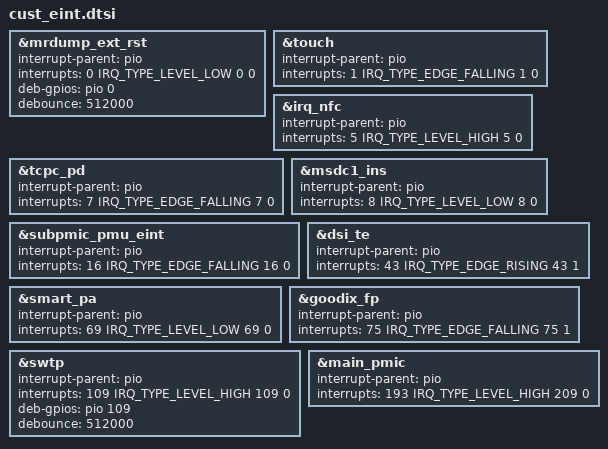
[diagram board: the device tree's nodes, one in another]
/*
 * Generated by MTK SP DrvGen Version: 3.5.160809 for MT6785.
 * 2024-09-29 07:04:17
 * Do Not Modify The File.
 * Copyright Mediatek Inc. (c) 2016.
*/

/*************************
 * EINT DTSI File
*************************/

#include <dt-bindings/interrupt-controller/irq.h>
#include <dt-bindings/interrupt-controller/arm-gic.h>

&mrdump_ext_rst {
	interrupt-parent = <&pio>;
	interrupts = <0 IRQ_TYPE_LEVEL_LOW 0 0>;
	deb-gpios = <&pio 0 0>;
	debounce = <512000>;
	status = "okay";
};

&touch {
	interrupt-parent = <&pio>;
	interrupts = <1 IRQ_TYPE_EDGE_FALLING 1 0>;
	status = "okay";
};

&irq_nfc {
	interrupt-parent = <&pio>;
	interrupts = <5 IRQ_TYPE_LEVEL_HIGH 5 0>;
	status = "okay";
};

&tcpc_pd {
	interrupt-parent = <&pio>;
	interrupts = <7 IRQ_TYPE_EDGE_FALLING 7 0>;
	status = "okay";
};

&msdc1_ins {
	interrupt-parent = <&pio>;
	interrupts = <8 IRQ_TYPE_LEVEL_LOW 8 0>;
	status = "okay";
};

&subpmic_pmu_eint {
	interrupt-parent = <&pio>;
	interrupts = <16 IRQ_TYPE_EDGE_FALLING 16 0>;
	status = "okay";
};

&dsi_te {
	interrupt-parent = <&pio>;
	interrupts = <43 IRQ_TYPE_EDGE_RISING 43 1>;
	status = "okay";
};

&smart_pa {
	interrupt-parent = <&pio>;
	interrupts = <69 IRQ_TYPE_LEVEL_LOW 69 0>;
	status = "okay";
};

&goodix_fp {
	interrupt-parent = <&pio>;
	interrupts = <75 IRQ_TYPE_EDGE_FALLING 75 1>;
	status = "okay";
};

&swtp {
	interrupt-parent = <&pio>;
	interrupts = <109 IRQ_TYPE_LEVEL_HIGH 109 0>;
	deb-gpios = <&pio 109 0>;
	debounce = <512000>;
	status = "okay";
};

&main_pmic {
	interrupt-parent = <&pio>;
	interrupts = <193 IRQ_TYPE_LEVEL_HIGH 209 0>;
	status = "okay";
};

